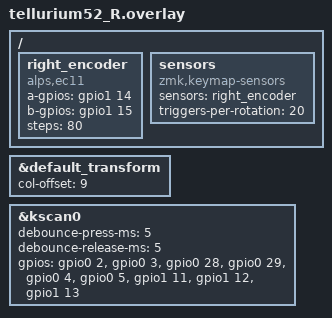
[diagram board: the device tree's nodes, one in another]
#include "tellurium52.dtsi"

// 【右手 = 子機(Peripheral)】
// 右手のキーは左手と座標が重ならないよう、列を9つずらす。
&default_transform {
    col-offset = <9>;
};

&kscan0 {
    // チャタリング除去。15msは反応が鈍く感じられたため控えめな5msにする。
    debounce-press-ms = <5>;
    debounce-release-ms = <5>;

    // XIAO nRF52840 のピン対応:
    //   D0=P0.02 D1=P0.03 D2=P0.28 D3=P0.29 D4=P0.04
    //   D5=P0.05 D6=P1.11 D7=P1.12 D8=P1.13
    gpios
        = <&gpio0  2 GPIO_ACTIVE_HIGH> // D0 = Row0
        , <&gpio0  3 GPIO_ACTIVE_HIGH> // D1 = Row1
        , <&gpio0 28 GPIO_ACTIVE_HIGH> // D2 = Row2
        , <&gpio0 29 GPIO_ACTIVE_HIGH> // D3 = Row3
        , <&gpio0  4 GPIO_ACTIVE_HIGH> // D4 = Row4
        , <&gpio0  5 GPIO_ACTIVE_HIGH> // D5 = Col0
        , <&gpio1 11 GPIO_ACTIVE_HIGH> // D6 = Col1
        , <&gpio1 12 GPIO_ACTIVE_HIGH> // D7 = Col2
        , <&gpio1 13 GPIO_ACTIVE_HIGH> // D8 = Col3
        ;
};

/ {
    // ロータリーエンコーダー(右手)。D9=P1.14, D10=P1.15
    right_encoder: right_encoder {
        compatible = "alps,ec11";
        a-gpios = <&gpio1 14 (GPIO_ACTIVE_HIGH | GPIO_PULL_UP)>;
        b-gpios = <&gpio1 15 (GPIO_ACTIVE_HIGH | GPIO_PULL_UP)>;
        steps = <80>;
        status = "okay";
    };

    sensors: sensors {
        compatible = "zmk,keymap-sensors";
        sensors = <&right_encoder>;
        // 左手と同じ。20 = 1ノッチ1回。40では1ノッチで2回反応してしまう。
        triggers-per-rotation = <20>;
    };
};
